# AT91SAM9CN11 register map
Vendor: Atmel; Series: SAM9CN; File version: 20130208
Registers are 32-bit, read-only, reset 0x0 unless marked. A register's access mark holds for its fields unless they carry their own. Offsets are from the block's base; [hi:lo] are bit positions; {n}, {i} and the like mark numbered series; 'fields as' and 'values as' point back to an identical list.

## PMC — Power Management Controller
Base 0xFFFFFC00
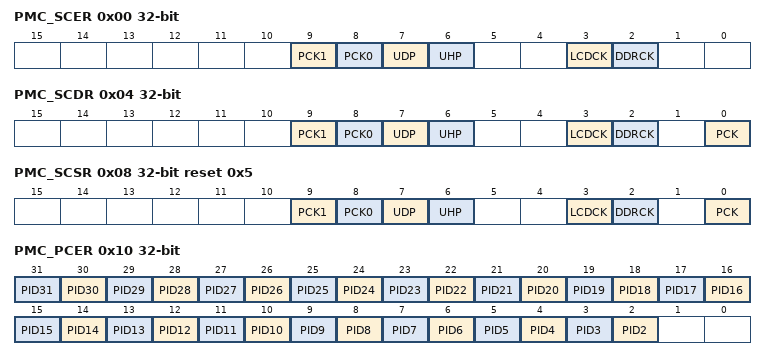
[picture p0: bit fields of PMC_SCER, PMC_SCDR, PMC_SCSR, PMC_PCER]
0x00 PMC_SCER wo reset not defined — System Clock Enable Register
  [9] PCK1 — Programmable Clock 1 Output Enable
  [8] PCK0 — Programmable Clock 0 Output Enable
  [7] UDP — USB Device Clock Enable
  [6] UHP — USB Host OHCI Clocks Enable
  [3] LCDCK — LCD Clock Enable
  [2] DDRCK — DDR Clock Enable
0x04 PMC_SCDR wo reset not defined — System Clock Disable Register
  [9] PCK1 — Programmable Clock 1 Output Disable
  [8] PCK0 — Programmable Clock 0 Output Disable
  [7] UDP — USB Device Clock Enable
  [6] UHP — USB Host OHCI Clock Disable
  [3] LCDCK — LCD Clock Disable
  [2] DDRCK — DDR Clock Disable
  [0] PCK — Processor Clock Disable
0x08 PMC_SCSR reset 0x5 — System Clock Status Register
  [9] PCK1 — Programmable Clock 1 Output Status
  [8] PCK0 — Programmable Clock 0 Output Status
  [7] UDP — USB Device Port Clock Status
  [6] UHP — USB Host Port Clock Status
  [3] LCDCK — LCD Clock Status
  [2] DDRCK — DDR Clock Status
  [0] PCK — Processor Clock Status
0x10 PMC_PCER wo reset not defined — Peripheral Clock Enable Register
  [n] PID{n} (n=2..31) — Peripheral Clock {n} Enable
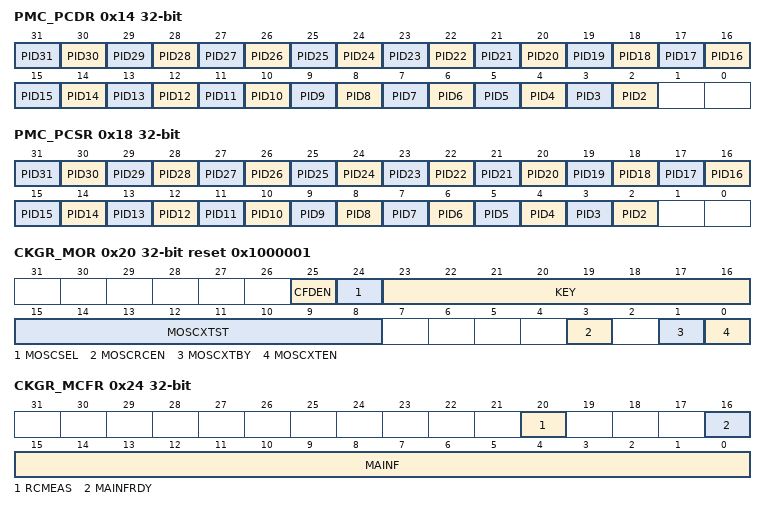
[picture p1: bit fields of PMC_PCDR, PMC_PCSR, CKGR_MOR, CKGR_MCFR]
0x14 PMC_PCDR wo reset not defined — Peripheral Clock Disable Register
  [n] PID{n} (n=2..31) — Peripheral Clock {n} Disable
0x18 PMC_PCSR — Peripheral Clock Status Register
  [n] PID{n} (n=2..31) — Peripheral Clock {n} Status
0x20 CKGR_MOR rw reset 0x1000001 — Main Oscillator Register
  [25] CFDEN — Clock Failure Detector Enable
  [24] MOSCSEL — Main Oscillator Selection
  [23:16] KEY — Password
  [15:8] MOSCXTST — Main Crystal Oscillator Start-up Time
  [3] MOSCRCEN — Main On-Chip RC Oscillator Enable
  [1] MOSCXTBY — Main Crystal Oscillator Bypass
  [0] MOSCXTEN — Main Crystal Oscillator Enable
0x24 CKGR_MCFR rw — Main Clock Frequency Register
  [20] RCMEAS — RC Measure
  [16] MAINFRDY — Main Clock Ready
  [15:0] MAINF — Main Clock Frequency
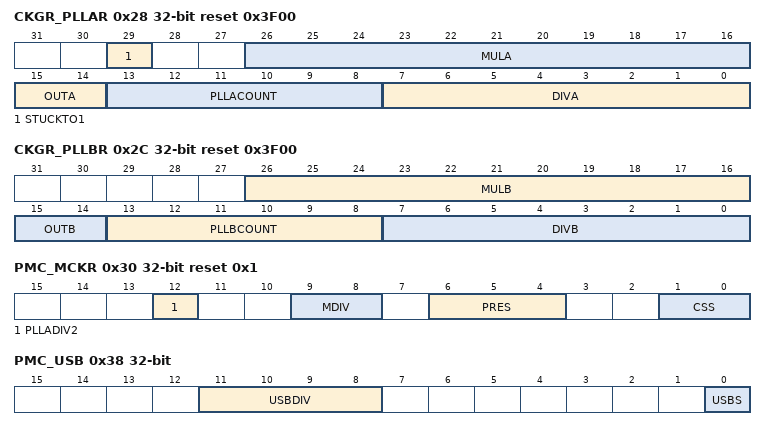
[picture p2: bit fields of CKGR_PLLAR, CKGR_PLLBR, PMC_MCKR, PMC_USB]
0x28 CKGR_PLLAR rw reset 0x3F00 — PLLA Register
  [29] STUCKTO1
  [26:16] MULA — PLLA Multiplier
  [15:14] OUTA — PLLA Clock Frequency Range
  [13:8] PLLACOUNT — PLLA Counter
  [7:0] DIVA — Divider A
0x2C CKGR_PLLBR rw reset 0x3F00 — PLLB Register
  [26:16] MULB — PLLB Multiplier
  [15:14] OUTB — PLLB Clock Frequency Range
  [13:8] PLLBCOUNT — PLLB Counter
  [7:0] DIVB — Divider B
0x30 PMC_MCKR rw reset 0x1 — Master Clock Register
  [12] PLLADIV2 — PLLA divisor by 2
    0=NOT_DIV2 (PLLA clock frequency is divided by 1.); 1=DIV2 (PLLA clock frequency is divided by 2.)
  [9:8] MDIV — Master Clock Division
    0=EQ_PCK (Master Clock is Prescaler Output Clock divided by 1.Warning: SysClk DDR and DDRCK are not available.); 1=PCK_DIV2 (Master Clock is Prescaler Output Clock divided by 2.SysClk DDR is equal to 2 x MCK. DDRCK is equal to MCK.); 2=PCK_DIV4 (Master Clock is Prescaler Output Clock divided by 4.SysClk DDR is equal to 2 x MCK. DDRCK is equal to MCK.); 3=PCK_DIV3 (Master Clock is Prescaler Output Clock divided by 3.SysClk DDR is equal to 2 x MCK. DDRCK is equal to MCK.)
  [6:4] PRES — Master/Processor Clock Prescaler
    0=CLOCK_DIV1 (Selected clock); 1=CLOCK_DIV2 (Selected clock divided by 2); 2=CLOCK_DIV4 (Selected clock divided by 4); 3=CLOCK_DIV8 (Selected clock divided by 8); 4=CLOCK_DIV16 (Selected clock divided by 16); 5=CLOCK_DIV32 (Selected clock divided by 32); 6=CLOCK_DIV64 (Selected clock divided by 64)
  [1:0] CSS — Master/Processor Clock Source Selection
    0=SLOW_CLK (Slow Clock is selected); 1=MAIN_CLK (Main Clock is selected); 2=PLLA_CLK (PLLACK/PLLADIV2 is selected); 3=PLLB_CLK (PLLBCK is selected)
0x38 PMC_USB rw — USB Clock Register
  [11:8] USBDIV — Divider for USB Clock
  [0] USBS — USB OHCI Input Clock Selection
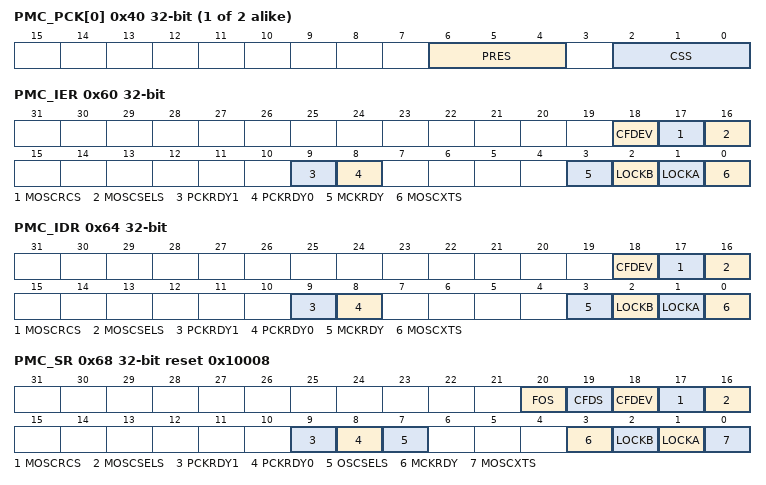
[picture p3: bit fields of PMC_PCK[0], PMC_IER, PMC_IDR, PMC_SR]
{0x40+4i} PMC_PCK[{i}] (i=0..1) rw reset not defined — Programmable Clock 0 Register
  [6:4] PRES — Programmable Clock Prescaler
    values as PMC_MCKR.PRES
  [2:0] CSS — Master Clock Source Selection
    0=SLOW_CLK (Slow Clock is selected); 1=MAIN_CLK (Main Clock is selected); 2=PLLA_CLK (PLLACK/PLLADIV2 is selected); 3=PLLB_CLK (PLLBCK is selected); 4=MCK_CLK (Master Clock is selected)
0x60 PMC_IER wo reset not defined — Interrupt Enable Register
  [18] CFDEV — Clock Failure Detector Event Interrupt Enable
  [17] MOSCRCS — Main On-Chip RC Status Interrupt Enable
  [16] MOSCSELS — Main Oscillator Selection Status Interrupt Enable
  [9] PCKRDY1 — Programmable Clock Ready 1 Interrupt Enable
  [8] PCKRDY0 — Programmable Clock Ready 0 Interrupt Enable
  [3] MCKRDY — Master Clock Ready Interrupt Enable
  [2] LOCKB — PLLB Lock Interrupt Enable
  [1] LOCKA — PLLA Lock Interrupt Enable
  [0] MOSCXTS — Main Crystal Oscillator Status Interrupt Enable
0x64 PMC_IDR wo reset not defined — Interrupt Disable Register
  [18] CFDEV — Clock Failure Detector Event Interrupt Disable
  [17] MOSCRCS — Main On-Chip RC Status Interrupt Disable
  [16] MOSCSELS — Main Oscillator Selection Status Interrupt Disable
  [9] PCKRDY1 — Programmable Clock Ready 1 Interrupt Disable
  [8] PCKRDY0 — Programmable Clock Ready 0 Interrupt Disable
  [3] MCKRDY — Master Clock Ready Interrupt Disable
  [2] LOCKB — PLLB Lock Interrupt Disable
  [1] LOCKA — PLLA Lock Interrupt Disable
  [0] MOSCXTS — Main Crystal Oscillator Status Interrupt Disable
0x68 PMC_SR reset 0x10008 — Status Register
  [20] FOS — Clock Failure Detector Fault Output Status
  [19] CFDS — Clock Failure Detector Status
  [18] CFDEV — Clock Failure Detector Event
  [17] MOSCRCS — Main On-Chip RC Oscillator Status
  [16] MOSCSELS — Main Oscillator Selection Status
  [9] PCKRDY1 — Programmable Clock Ready Status
  [8] PCKRDY0 — Programmable Clock Ready Status
  [7] OSCSELS — Slow Clock Oscillator Selection
  [3] MCKRDY — Master Clock Status
  [2] LOCKB — PLLB Lock Status
  [1] LOCKA — PLLA Lock Status
  [0] MOSCXTS — Main XTAL Oscillator Status
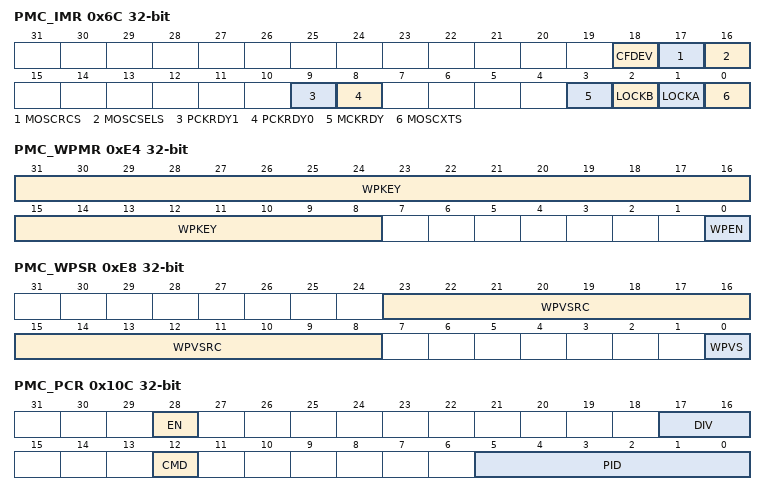
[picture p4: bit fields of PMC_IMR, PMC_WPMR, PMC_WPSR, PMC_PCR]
0x6C PMC_IMR — Interrupt Mask Register
  [18] CFDEV — Clock Failure Detector Event Interrupt Mask
  [17] MOSCRCS — Main On-Chip RC Status Interrupt Mask
  [16] MOSCSELS — Main Oscillator Selection Status Interrupt Mask
  [9] PCKRDY1 — Programmable Clock Ready 1 Interrupt Mask
  [8] PCKRDY0 — Programmable Clock Ready 0 Interrupt Mask
  [3] MCKRDY — Master Clock Ready Interrupt Mask
  [2] LOCKB — PLLB Lock Interrupt Mask
  [1] LOCKA — PLLA Lock Interrupt Mask
  [0] MOSCXTS — Main Crystal Oscillator Status Interrupt Mask
0x80 PMC_PLLICPR wo reset 0x1000100 — PLL Charge Pump Current Register
  [0] ICPLLA — Charge Pump Current
0xE4 PMC_WPMR rw — Write Protect Mode Register
  [31:8] WPKEY — Write Protect KEY
  [0] WPEN — Write Protect Enable
0xE8 PMC_WPSR — Write Protect Status Register
  [23:8] WPVSRC — Write Protect Violation Source
  [0] WPVS — Write Protect Violation Status
0x10C PMC_PCR rw — Peripheral Control Register
  [28] EN — Enable
  [17:16] DIV — Divisor value
    0=PERIPH_DIV_MCK (Peripheral clock is MCK); 1=PERIPH_DIV2_MCK (Peripheral clock is MCK/2); 2=PERIPH_DIV4_MCK (Peripheral clock is MCK/4); 3=PERIPH_DIV8_MCK (Peripheral clock is MCK/8)
  [12] CMD — Command
  [5:0] PID — Peripheral ID
